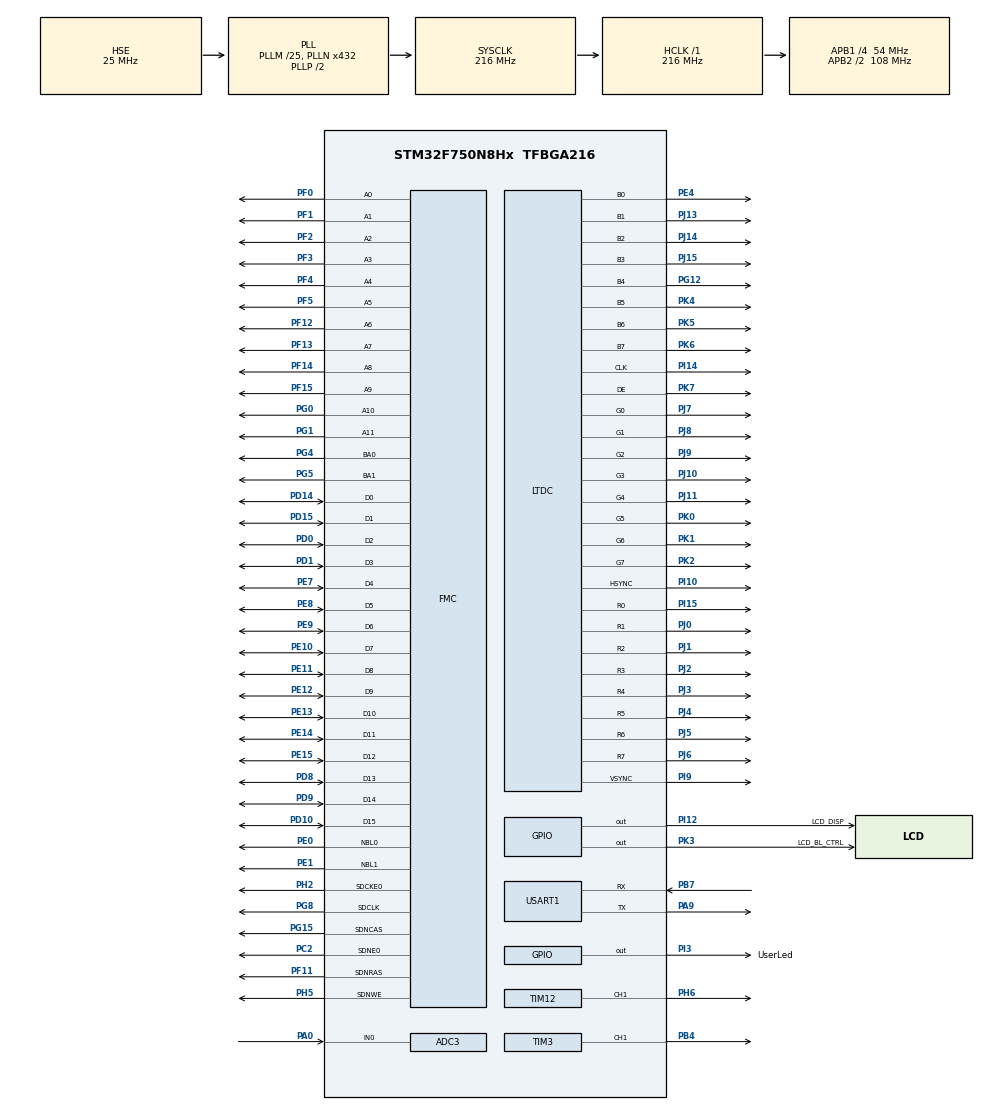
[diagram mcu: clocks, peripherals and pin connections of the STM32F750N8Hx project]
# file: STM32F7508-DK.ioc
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SH.FMC_D7_DA7.0=FMC_D7,sd-16b-d1
PK5.Signal=LTDC_B6
VP_SYS_VS_tim6.Mode=TIM6
PJ9.Mode=RGB888
SH.FMC_A0.0=FMC_A0,12b-sda1
CORTEX_M7.BaseAddress-Cortex_Memory_Protection_Unit_Region3_Settings=0x90000000
NVIC.TIM6_DAC_IRQn=true\:0\:0\:false\:false\:true\:false\:false\:true
PK0.Mode=RGB888
PG8.Signal=FMC_SDCLK
PG4.Signal=FMC_A14_BA0
PJ10.GPIO_Speed=GPIO_SPEED_FREQ_HIGH
PG0.Signal=FMC_A10
CORTEX_M7.PREFETCH_ENABLE=1
CORTEX_M7.AccessPermission-Cortex_Memory_Protection_Unit_Region2_Settings=MPU_REGION_FULL_ACCESS
PJ8.GPIO_Speed=GPIO_SPEED_FREQ_HIGH
PK1.Signal=LTDC_G6
SH.FMC_D5_DA5.0=FMC_D5,sd-16b-d1
VP_STMicroelectronics.X-CUBE-TOUCHGFX_VS_GraphicsJjApplication_4.16.0.Mode=GraphicsJjApplication
CORTEX_M7.Enable-Cortex_Memory_Protection_Unit_Region5_Settings=MPU_REGION_ENABLE
RCC.SYSCLKSource=RCC_SYSCLKSOURCE_PLLCLK
PJ10.Signal=LTDC_G3
SH.FMC_A15_BA1.0=FMC_BA1,FourSdramBanks1
SH.FMC_D9_DA9.0=FMC_D9,sd-16b-d1
STMicroelectronics.X-CUBE-TOUCHGFX.4.16.0.tgfx_hardware_accelerator=dma_2d
CORTEX_M7.Enable-Cortex_Memory_Protection_Unit_Region0_Settings=MPU_REGION_ENABLE
FREERTOS.INCLUDE_pcTaskGetTaskName=0
CORTEX_M7.IsBufferable-Cortex_Memory_Protection_Unit_Region1_Settings=MPU_ACCESS_NOT_BUFFERABLE
PH5.Signal=FMC_SDNWE
NVIC.DMA2D_IRQn=true\:5\:0\:true\:false\:true\:false\:true\:true
SH.FMC_SDNWE.0=FMC_SDNWE,12b-sda1
SH.FMC_D11_DA11.0=FMC_D11,sd-16b-d1
PJ5.Mode=RGB888
RCC.APB2TimFreq_Value=216000000
PH1/OSC_OUT.Signal=RCC_OSC_OUT
PD0.Signal=FMC_D2_DA2
PD8.Signal=FMC_D13_DA13
PE1.Signal=FMC_NBL1
CORTEX_M7.Size-Cortex_Memory_Protection_Unit_Region5_Settings=MPU_REGION_SIZE_1MB
PJ14.Mode=RGB888
LTDC.PixelFormat_L0=LTDC_PIXEL_FORMAT_RGB565
PK7.Mode=RGB888
SH.S_TIM12_CH1.0=TIM12_CH1,PWM Generation1 CH1
FREERTOS.INCLUDE_xQueueGetMutexHolder=1
PJ2.Mode=RGB888
PE9.Signal=FMC_D6_DA6
SH.FMC_A2.0=FMC_A2,12b-sda1
PI3.Signal=GPIO_Output
PJ1.GPIO_Speed=GPIO_SPEED_FREQ_HIGH
SH.FMC_D1_DA1.0=FMC_D1,sd-16b-d1
PF3.Signal=FMC_A3
CORTEX_M7.Size-Cortex_Memory_Protection_Unit_Region4_Settings=MPU_REGION_SIZE_16MB
PE10.Signal=FMC_D7_DA7
LTDC.HSync=41
CORTEX_M7.DisableExec-Cortex_Memory_Protection_Unit_Region1_Settings=MPU_INSTRUCTION_ACCESS_DISABLE
PJ14.Signal=LTDC_B2
Mcu.Package=TFBGA216
PI10.GPIO_Speed=GPIO_SPEED_FREQ_HIGH
NVIC.TimeBase=TIM6_DAC_IRQn
PK6.GPIO_Speed=GPIO_SPEED_FREQ_HIGH
PJ4.Signal=LTDC_R5
ADC3.Rank-0\#ChannelRegularConversion=1
NVIC.TimeBaseIP=TIM6
CORTEX_M7.BaseAddress-Cortex_Memory_Protection_Unit_Region4_Settings=0x90000000
SH.FMC_A1.0=FMC_A1,12b-sda1
PH2.Signal=FMC_SDCKE0
RCC.APB2CLKDivider=RCC_HCLK_DIV2
PJ3.GPIO_Speed=GPIO_SPEED_FREQ_HIGH
SH.FMC_SDCLK.0=FMC_SDCLK,12b-sda1
LTDC.VSync=10
PF14.Signal=FMC_A8
RCC.APB1TimFreq_Value=108000000
CORTEX_M7.Enable-Cortex_Memory_Protection_Unit_Region1_Settings=MPU_REGION_ENABLE
VP_DMA2D_VS_DMA2D.Mode=DMA2D_Activate
PJ13.Mode=RGB888
PJ1.Mode=RGB888
SH.FMC_D3_DA3.0=FMC_D3,sd-16b-d1
PD15.Signal=FMC_D1_DA1
CORTEX_M7.IsBufferable-Cortex_Memory_Protection_Unit_Region0_Settings=MPU_ACCESS_BUFFERABLE
PJ5.GPIO_Speed=GPIO_SPEED_FREQ_HIGH
PG12.Signal=LTDC_B4
PI14.GPIO_Speed=GPIO_SPEED_FREQ_HIGH
FREERTOS.INCLUDE_xTimerPendFunctionCall=1
CORTEX_M7.AccessPermission-Cortex_Memory_Protection_Unit_Region3_Settings=MPU_REGION_NO_ACCESS
PK4.Signal=LTDC_B5
SH.FMC_A4.0=FMC_A4,12b-sda1
FREERTOS.Tasks01=TouchGFXTask,24,8192,TouchGFX_Task,As weak,NULL,Dynamic,NULL,NULL;BlinkTask,8,128,StartBlinkTask,Default,NULL,Dynamic,NULL,NULL;PwmTask,24,128,StartPwmTask,Default,NULL,Dynamic,NULL,NULL
CORTEX_M7.IsCacheable-Cortex_Memory_Protection_Unit_Region5_Settings=MPU_ACCESS_CACHEABLE
PG5.Signal=FMC_A15_BA1
SH.FMC_D10_DA10.0=FMC_D10,sd-16b-d1
CORTEX_M7.IsBufferable-Cortex_Memory_Protection_Unit_Region2_Settings=MPU_ACCESS_BUFFERABLE
FREERTOS.INCLUDE_vTaskDelayUntil=1
CORTEX_M7.IsCacheable-Cortex_Memory_Protection_Unit_Region0_Settings=MPU_ACCESS_CACHEABLE
CORTEX_M7.Enable-Cortex_Memory_Protection_Unit_Region4_Settings=MPU_REGION_ENABLE
PI10.Mode=RGB888
PC2.Signal=FMC_SDNE0
PD1.Signal=FMC_D3_DA3
PI12.Signal=GPIO_Output
STMicroelectronics.X-CUBE-TOUCHGFX.4.16.0.tgfx_buffering_strategy=Double
RCC.APB1CLKDivider=RCC_HCLK_DIV4
PJ11.Signal=LTDC_G4
LTDC.ImageWidth_L0=480
PD10.Signal=FMC_D15_DA15
PJ6.Mode=RGB888
SH.FMC_A3.0=FMC_A3,12b-sda1
PJ7.Signal=LTDC_G0
PJ3.Signal=LTDC_R4
SH.FMC_D15_DA15.0=FMC_D15,sd-16b-d1
CORTEX_M7.ART_ACCLERATOR_ENABLE=1
PA9.Signal=USART1_TX
CORTEX_M7.IsCacheable-Cortex_Memory_Protection_Unit_Region3_Settings=MPU_ACCESS_NOT_CACHEABLE
CORTEX_M7.BaseAddress-Cortex_Memory_Protection_Unit_Region0_Settings=0x20000000
CORTEX_M7.AccessPermission-Cortex_Memory_Protection_Unit_Region5_Settings=MPU_REGION_FULL_ACCESS
PJ13.GPIO_Speed=GPIO_SPEED_FREQ_HIGH
CORTEX_M7.Enable-Cortex_Memory_Protection_Unit_Region2_Settings=MPU_REGION_ENABLE
FREERTOS.MEMORY_ALLOCATION=2
PJ15.Signal=LTDC_B3
PJ14.GPIO_Speed=GPIO_SPEED_FREQ_HIGH
SH.FMC_A6.0=FMC_A6,12b-sda1
PE14.Signal=FMC_D11_DA11
PE15.Signal=FMC_D12_DA12
PE8.Signal=FMC_D5_DA5
CORTEX_M7.AccessPermission-Cortex_Memory_Protection_Unit_Region0_Settings=MPU_REGION_FULL_ACCESS
PF13.Signal=FMC_A7
SH.FMC_SDNCAS.0=FMC_SDNCAS,12b-sda1
PJ15.Mode=RGB888
PK1.GPIO_Speed=GPIO_SPEED_FREQ_HIGH
FREERTOS.configUSE_COUNTING_SEMAPHORES=1
PK4.Mode=RGB888
SH.FMC_A5.0=FMC_A5,12b-sda1
LTDC.Alpha_L0=255
PJ6.GPIO_Speed=GPIO_SPEED_FREQ_HIGH
PJ8.Signal=LTDC_G1
ProjectManager.HeapSize=0x1000
PK3.GPIO_Label=LCD_BL_CTRL
PH6.Signal=S_TIM12_CH1
FREERTOS.configUSE_RECURSIVE_MUTEXES=1
PG12.GPIO_Speed=GPIO_SPEED_FREQ_HIGH
STMicroelectronics.X-CUBE-TOUCHGFX.4.16.0.tgfx_vsync=vsync_ltdc
PJ10.Mode=RGB888
CORTEX_M7.DisableExec-Cortex_Memory_Protection_Unit_Region2_Settings=MPU_INSTRUCTION_ACCESS_DISABLE
NVIC.PriorityGroup=NVIC_PRIORITYGROUP_4
CORTEX_M7.IsBufferable-Cortex_Memory_Protection_Unit_Region5_Settings=MPU_ACCESS_BUFFERABLE
PJ4.Mode=RGB888
PC15/OSC32_OUT.Signal=RCC_OSC32_OUT
PF4.Signal=FMC_A4
PK5.GPIO_Speed=GPIO_SPEED_FREQ_HIGH
Mcu.Family=STM32F7
PK7.Signal=LTDC_DE
PK3.Signal=GPIO_Output
SH.FMC_A8.0=FMC_A8,12b-sda1
CORTEX_M7.DisableExec-Cortex_Memory_Protection_Unit_Region4_Settings=MPU_INSTRUCTION_ACCESS_DISABLE
RCC.CortexFreq_Value=216000000
PK2.GPIO_Speed=GPIO_SPEED_FREQ_HIGH
SH.FMC_D14_DA14.0=FMC_D14,sd-16b-d1
LTDC.HBP=13
SH.FMC_NBL0.0=FMC_NBL0,Sd2ByteEnable1
SH.FMC_D6_DA6.0=FMC_D6,sd-16b-d1
PA0/WKUP.Signal=ADCx_IN0
PC14/OSC32_IN.Mode=LSE-External-Oscillator
SH.FMC_A14_BA0.0=FMC_BA0,FourSdramBanks1
SH.FMC_A11.0=FMC_A11,12b-sda1
PI9.GPIO_Speed=GPIO_SPEED_FREQ_HIGH
PJ2.GPIO_Speed=GPIO_SPEED_FREQ_HIGH
ADC3.Channel-0\#ChannelRegularConversion=ADC_CHANNEL_0
PJ9.GPIO_Speed=GPIO_SPEED_FREQ_HIGH
PG15.Signal=FMC_SDNCAS
CORTEX_M7.IsBufferable-Cortex_Memory_Protection_Unit_Region3_Settings=MPU_ACCESS_NOT_BUFFERABLE
ProjectManager.StackSize=0x1000
VP_FREERTOS_VS_CMSIS_V2.Mode=CMSIS_V2
PJ6.Signal=LTDC_R7
PJ11.GPIO_Speed=GPIO_SPEED_FREQ_HIGH
SH.FMC_A7.0=FMC_A7,12b-sda1
PJ2.Signal=LTDC_R3
STMicroelectronics.X-CUBE-TOUCHGFX.4.16.0.tgfx_location=By Address
PH0/OSC_IN.Mode=HSE-External-Oscillator
RCC.HCLKFreq_Value=216000000
SH.FMC_NBL1.0=FMC_NBL1,Sd2ByteEnable1
LTDC.WindowX1_L0=480
PF12.Signal=FMC_A6
PI9.Mode=RGB888
PK2.Mode=RGB888
SH.FMC_A10.0=FMC_A10,12b-sda1
RCC.AHBFreq_Value=216000000
TIM3.Channel-PWM\ Generation1\ CH1=TIM_CHANNEL_1
CORTEX_M7.BaseAddress-Cortex_Memory_Protection_Unit_Region5_Settings=0x90000000
RCC.HSE_VALUE=25000000
FREERTOS.configUSE_TIMERS=1
STMicroelectronics.X-CUBE-TOUCHGFX.4.16.0.tgfx_display_interface=disp_ltdc
SH.FMC_D8_DA8.0=FMC_D8,sd-16b-d1
CORTEX_M7.Size-Cortex_Memory_Protection_Unit_Region2_Settings=MPU_REGION_SIZE_8MB
PI14.Mode=RGB888
SH.FMC_D2_DA2.0=FMC_D2,sd-16b-d1
CORTEX_M7.IsCacheable-Cortex_Memory_Protection_Unit_Region2_Settings=MPU_ACCESS_CACHEABLE
PE13.Signal=FMC_D10_DA10
PE4.GPIO_Speed=GPIO_SPEED_FREQ_HIGH
PK6.Mode=RGB888
PF11.Signal=FMC_SDNRAS
PJ7.GPIO_Speed=GPIO_SPEED_FREQ_HIGH
LTDC.HFP=32
PB7.Signal=USART1_RX
SH.ADCx_IN0.0=ADC3_IN0,IN0
FREERTOS.INCLUDE_vTaskCleanUpResources=0
SH.S_TIM3_CH1.0=TIM3_CH1,PWM Generation1 CH1
PE4.Mode=RGB888
SH.FMC_SDNRAS.0=FMC_SDNRAS,12b-sda1
DMA2D.ColorMode=DMA2D_OUTPUT_ARGB8888
LTDC.ActiveW=480
PH1/OSC_OUT.Mode=HSE-External-Oscillator
PE4.Signal=LTDC_B0
CORTEX_M7.DisableExec-Cortex_Memory_Protection_Unit_Region0_Settings=MPU_INSTRUCTION_ACCESS_DISABLE
FREERTOS.configTOTAL_HEAP_SIZE=65536
STMicroelectronics.X-CUBE-TOUCHGFX.4.16.0.tgfx_address1=0xC0000000
STMicroelectronics.X-CUBE-TOUCHGFX.4.16.0.tgfx_address2=0xC003FC00
PJ0.Mode=RGB888
PJ9.Signal=LTDC_G2
SH.FMC_D0_DA0.0=FMC_D0,sd-16b-d1
CORTEX_M7.BaseAddress-Cortex_Memory_Protection_Unit_Region1_Settings=0xC0000000
PC14/OSC32_IN.Signal=RCC_OSC32_IN
SH.FMC_A9.0=FMC_A9,12b-sda1
PJ1.Signal=LTDC_R2
SH.FMC_D4_DA4.0=FMC_D4,sd-16b-d1
PI12.GPIO_Label=LCD_DISP
ADC3.ClockPrescaler=ADC_CLOCK_SYNC_PCLK_DIV8
RCC.PLLSAIN=100
PF5.Signal=FMC_A5
CORTEX_M7.Size-Cortex_Memory_Protection_Unit_Region1_Settings=MPU_REGION_SIZE_512MB
RCC.PLLSAIR=5
PJ7.Mode=RGB888
PF0.Signal=FMC_A0
PK4.GPIO_Speed=GPIO_SPEED_FREQ_HIGH
PH2.Mode=SdramChipSelect1_1
PE7.Signal=FMC_D4_DA4
PI15.Mode=RGB888
PB4.Signal=S_TIM3_CH1
PK1.Mode=RGB888
RCC.PLLSourceVirtual=RCC_PLLSOURCE_HSE
PK6.Signal=LTDC_B7
NVIC.LTDC_IRQn=true\:5\:0\:true\:false\:true\:false\:true\:true
PK2.Signal=LTDC_G7
CORTEX_M7.CPU_ICache=Enabled
LTDC.WindowY1_L0=272
PJ8.Mode=RGB888
PG1.Signal=FMC_A11
PI14.Signal=LTDC_CLK
PC2.Mode=SdramChipSelect1_1
PI10.Signal=LTDC_HSYNC
PD9.Signal=FMC_D14_DA14
FREERTOS.configUSE_APPLICATION_TASK_TAG=1
CORTEX_M7.BaseAddress-Cortex_Memory_Protection_Unit_Region2_Settings=0xC0000000
PJ11.Mode=RGB888
FREERTOS.INCLUDE_uxTaskGetStackHighWaterMark=1
USART1.VirtualMode-Asynchronous=VM_ASYNC
FREERTOS.configUSE_IDLE_HOOK=1
CORTEX_M7.MPU_Control=MPU_PRIVILEGED_DEFAULT
PA9.Mode=Asynchronous
PK0.GPIO_Speed=GPIO_SPEED_FREQ_HIGH
ADC3.SamplingTime-0\#ChannelRegularConversion=ADC_SAMPLETIME_3CYCLES
PJ0.GPIO_Speed=GPIO_SPEED_FREQ_HIGH
CORTEX_M7.IsBufferable-Cortex_Memory_Protection_Unit_Region4_Settings=MPU_ACCESS_BUFFERABLE
ProjectManager.TargetToolchain=STM32CubeIDE
FREERTOS.configUSE_TRACE_FACILITY=1
SH.FMC_D13_DA13.0=FMC_D13,sd-16b-d1
LTDC.ActiveH=272
CORTEX_M7.DisableExec-Cortex_Memory_Protection_Unit_Region3_Settings=MPU_INSTRUCTION_ACCESS_DISABLE
PF2.Signal=FMC_A2
STMicroelectronics.X-CUBE-TOUCHGFX.4.16.0.ApplicationCcGraphicsJjApplication=TouchGFXOoGenerator
RCC.USBFreq_Value=216000000
PE11.Signal=FMC_D8_DA8
PK0.Signal=LTDC_G5
PK5.Mode=RGB888
board=custom
PG12.Mode=RGB888
PJ15.GPIO_Speed=GPIO_SPEED_FREQ_HIGH
RCC.VCOOutputFreq_Value=432000000
PI9.Signal=LTDC_VSYNC
PJ3.Mode=RGB888
FREERTOS.INCLUDE_eTaskGetState=1
PH0/OSC_IN.Signal=RCC_OSC_IN
TIM12.Channel-PWM\ Generation1\ CH1=TIM_CHANNEL_1
RCC.APB2Freq_Value=108000000
LTDC.Layers=0
PK7.GPIO_Speed=GPIO_SPEED_FREQ_HIGH
SH.FMC_D12_DA12.0=FMC_D12,sd-16b-d1
PF15.Signal=FMC_A9
PF1.Signal=FMC_A1
PJ0.Signal=LTDC_R1
PE0.Signal=FMC_NBL0
Mcu.Name=STM32F750N8Hx
CORTEX_M7.Size-Cortex_Memory_Protection_Unit_Region0_Settings=MPU_REGION_SIZE_512KB
PE12.Signal=FMC_D9_DA9
FREERTOS.INCLUDE_xSemaphoreGetMutexHolder=1
CORTEX_M7.AccessPermission-Cortex_Memory_Protection_Unit_Region1_Settings=MPU_REGION_NO_ACCESS
CORTEX_M7.IsCacheable-Cortex_Memory_Protection_Unit_Region1_Settings=MPU_ACCESS_NOT_CACHEABLE
PD14.Signal=FMC_D0_DA0
RCC.SYSCLKFreq_VALUE=216000000
PI15.GPIO_Speed=GPIO_SPEED_FREQ_HIGH
PJ5.Signal=LTDC_R6
PC15/OSC32_OUT.Mode=LSE-External-Oscillator
PB7.Mode=Asynchronous
CORTEX_M7.Enable-Cortex_Memory_Protection_Unit_Region3_Settings=MPU_REGION_ENABLE
CORTEX_M7.Size-Cortex_Memory_Protection_Unit_Region3_Settings=MPU_REGION_SIZE_512MB
RCC.HSI_VALUE=16000000
PI3.GPIO_Label=UserLed
RCC.PLLM=25
RCC.PLLN=432
PI15.Signal=LTDC_R0
CORTEX_M7.CPU_DCache=Enabled
PJ4.GPIO_Speed=GPIO_SPEED_FREQ_HIGH
RCC.APB1Freq_Value=54000000
ADC3.NbrOfConversionFlag=1
VP_CRC_VS_CRC.Mode=CRC_Activate
LTDC.ImageHeight_L0=272
CORTEX_M7.AccessPermission-Cortex_Memory_Protection_Unit_Region4_Settings=MPU_REGION_FULL_ACCESS
PJ13.Signal=LTDC_B1
CORTEX_M7.IsCacheable-Cortex_Memory_Protection_Unit_Region4_Settings=MPU_ACCESS_CACHEABLE

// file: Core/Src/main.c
/* USER CODE BEGIN Header */
/**
  ******************************************************************************
  * @file           : main.c
  * @brief          : Main program body
  ******************************************************************************
  * @attention
  *
  * <h2><center>&copy; Copyright (c) 2020 STMicroelectronics.
  * All rights reserved.</center></h2>
  *
  * This software component is licensed by ST under Ultimate Liberty license
  * SLA0044, the "License"; You may not use this file except in compliance with
  * the License. You may obtain a copy of the License at:
  *                             www.st.com/SLA0044
  *
  ******************************************************************************
  */
/* USER CODE END Header */
#include "main.h"
#include "cmsis_os.h"
#include "app_touchgfx.h"

/* USER CODE BEGIN Includes */
#include "stm32f7508_discovery_sdram.h"
/* USER CODE END Includes */

ADC_HandleTypeDef hadc3;

CRC_HandleTypeDef hcrc;

DMA2D_HandleTypeDef hdma2d;

LTDC_HandleTypeDef hltdc;

TIM_HandleTypeDef htim3;
TIM_HandleTypeDef htim12;

UART_HandleTypeDef huart1;

SDRAM_HandleTypeDef hsdram1;

/* Definitions for TouchGFXTask */
osThreadId_t TouchGFXTaskHandle;
const osThreadAttr_t TouchGFXTask_attributes = {
  .name = "TouchGFXTask",
  .priority = (osPriority_t) osPriorityNormal,
  .stack_size = 8192 * 4
};
/* Definitions for BlinkTask */
osThreadId_t BlinkTaskHandle;
const osThreadAttr_t BlinkTask_attributes = {
  .name = "BlinkTask",
  .priority = (osPriority_t) osPriorityLow,
  .stack_size = 128 * 4
};
/* Definitions for PwmTask */
osThreadId_t PwmTaskHandle;
const osThreadAttr_t PwmTask_attributes = {
  .name = "PwmTask",
  .priority = (osPriority_t) osPriorityNormal,
  .stack_size = 128 * 4
};

void SystemClock_Config(void);
static void MPU_Config(void);
static void MX_GPIO_Init(void);
static void MX_CRC_Init(void);
static void MX_DMA2D_Init(void);
static void MX_FMC_Init(void);
static void MX_LTDC_Init(void);
static void MX_USART1_UART_Init(void);
static void MX_TIM3_Init(void);
static void MX_ADC3_Init(void);
static void MX_TIM12_Init(void);
void TouchGFX_Task(void *argument);
void StartBlinkTask(void *argument);
void StartPwmTask(void *argument);

/* USER CODE BEGIN PFP */

void setPWM(TIM_HandleTypeDef timer, uint32_t channel, uint16_t period, uint16_t pulse);

/* USER CODE END PFP */

int main(void)
{

  /* MPU Configuration--------------------------------------------------------*/
  MPU_Config();

  /* Enable I-Cache---------------------------------------------------------*/
  SCB_EnableICache();

  /* Enable D-Cache---------------------------------------------------------*/
  SCB_EnableDCache();

  /* MCU Configuration--------------------------------------------------------*/

  /* Reset of all peripherals, Initializes the Flash interface and the Systick. */
  HAL_Init();

  /* Configure the system clock */
  SystemClock_Config();

  /* Initialize all configured peripherals */
  MX_GPIO_Init();
  MX_CRC_Init();
  MX_DMA2D_Init();
  MX_FMC_Init();
  MX_LTDC_Init();
  MX_USART1_UART_Init();
  MX_TIM3_Init();
  MX_ADC3_Init();
  MX_TIM12_Init();
  MX_TouchGFX_Init();

  /* Init scheduler */
  osKernelInitialize();

  /* Create the thread(s) */
  /* creation of TouchGFXTask */
  TouchGFXTaskHandle = osThreadNew(TouchGFX_Task, NULL, &TouchGFXTask_attributes);

  /* creation of BlinkTask */
  BlinkTaskHandle = osThreadNew(StartBlinkTask, NULL, &BlinkTask_attributes);

  /* creation of PwmTask */
  PwmTaskHandle = osThreadNew(StartPwmTask, NULL, &PwmTask_attributes);

  /* Start scheduler */
  osKernelStart();

  /* We should never get here as control is now taken by the scheduler */
  /* Infinite loop */
  while (1)
  {

  }
}

void SystemClock_Config(void)
{
  RCC_OscInitTypeDef RCC_OscInitStruct = {0};
  RCC_ClkInitTypeDef RCC_ClkInitStruct = {0};
  RCC_PeriphCLKInitTypeDef PeriphClkInitStruct = {0};

  /** Configure LSE Drive Capability
  */
  HAL_PWR_EnableBkUpAccess();
  /** Configure the main internal regulator output voltage
  */
  __HAL_RCC_PWR_CLK_ENABLE();
  __HAL_PWR_VOLTAGESCALING_CONFIG(PWR_REGULATOR_VOLTAGE_SCALE1);
  /** Initializes the RCC Oscillators according to the specified parameters
  * in the RCC_OscInitTypeDef structure.
  */
  RCC_OscInitStruct.OscillatorType = RCC_OSCILLATORTYPE_HSE;
  RCC_OscInitStruct.HSEState = RCC_HSE_ON;
  RCC_OscInitStruct.PLL.PLLState = RCC_PLL_ON;
  RCC_OscInitStruct.PLL.PLLSource = RCC_PLLSOURCE_HSE;
  RCC_OscInitStruct.PLL.PLLM = 25;
  RCC_OscInitStruct.PLL.PLLN = 432;
  RCC_OscInitStruct.PLL.PLLP = RCC_PLLP_DIV2;
  RCC_OscInitStruct.PLL.PLLQ = 2;
  if (HAL_RCC_OscConfig(&RCC_OscInitStruct) != HAL_OK)
  {
    Error_Handler();
  }
  /** Activate the Over-Drive mode
  */
  if (HAL_PWREx_EnableOverDrive() != HAL_OK)
  {
    Error_Handler();
  }
  /** Initializes the CPU, AHB and APB buses clocks
  */
  RCC_ClkInitStruct.ClockType = RCC_CLOCKTYPE_HCLK|RCC_CLOCKTYPE_SYSCLK
                              |RCC_CLOCKTYPE_PCLK1|RCC_CLOCKTYPE_PCLK2;
  RCC_ClkInitStruct.SYSCLKSource = RCC_SYSCLKSOURCE_PLLCLK;
  RCC_ClkInitStruct.AHBCLKDivider = RCC_SYSCLK_DIV1;
  RCC_ClkInitStruct.APB1CLKDivider = RCC_HCLK_DIV4;
  RCC_ClkInitStruct.APB2CLKDivider = RCC_HCLK_DIV2;

  if (HAL_RCC_ClockConfig(&RCC_ClkInitStruct, FLASH_LATENCY_7) != HAL_OK)
  {
    Error_Handler();
  }
  PeriphClkInitStruct.PeriphClockSelection = RCC_PERIPHCLK_LTDC|RCC_PERIPHCLK_USART1;
  PeriphClkInitStruct.PLLSAI.PLLSAIN = 100;
  PeriphClkInitStruct.PLLSAI.PLLSAIR = 5;
  PeriphClkInitStruct.PLLSAI.PLLSAIQ = 2;
  PeriphClkInitStruct.PLLSAI.PLLSAIP = RCC_PLLSAIP_DIV2;
  PeriphClkInitStruct.PLLSAIDivQ = 1;
  PeriphClkInitStruct.PLLSAIDivR = RCC_PLLSAIDIVR_2;
  PeriphClkInitStruct.Usart1ClockSelection = RCC_USART1CLKSOURCE_PCLK2;
  if (HAL_RCCEx_PeriphCLKConfig(&PeriphClkInitStruct) != HAL_OK)
  {
    Error_Handler();
  }
}

static void MX_ADC3_Init(void)
{

  ADC_ChannelConfTypeDef sConfig = {0};

  /** Configure the global features of the ADC (Clock, Resolution, Data Alignment and number of conversion)
  */
  hadc3.Instance = ADC3;
  hadc3.Init.ClockPrescaler = ADC_CLOCK_SYNC_PCLK_DIV8;
  hadc3.Init.Resolution = ADC_RESOLUTION_12B;
  hadc3.Init.ScanConvMode = ADC_SCAN_DISABLE;
  hadc3.Init.ContinuousConvMode = DISABLE;
  hadc3.Init.DiscontinuousConvMode = DISABLE;
  hadc3.Init.ExternalTrigConvEdge = ADC_EXTERNALTRIGCONVEDGE_NONE;
  hadc3.Init.ExternalTrigConv = ADC_SOFTWARE_START;
  hadc3.Init.DataAlign = ADC_DATAALIGN_RIGHT;
  hadc3.Init.NbrOfConversion = 1;
  hadc3.Init.DMAContinuousRequests = DISABLE;
  hadc3.Init.EOCSelection = ADC_EOC_SINGLE_CONV;
  if (HAL_ADC_Init(&hadc3) != HAL_OK)
  {
    Error_Handler();
  }
  /** Configure for the selected ADC regular channel its corresponding rank in the sequencer and its sample time.
  */
  sConfig.Channel = ADC_CHANNEL_0;
  sConfig.Rank = ADC_REGULAR_RANK_1;
  sConfig.SamplingTime = ADC_SAMPLETIME_3CYCLES;
  if (HAL_ADC_ConfigChannel(&hadc3, &sConfig) != HAL_OK)
  {
    Error_Handler();
  }

}

static void MX_CRC_Init(void)
{

  hcrc.Instance = CRC;
  hcrc.Init.DefaultPolynomialUse = DEFAULT_POLYNOMIAL_ENABLE;
  hcrc.Init.DefaultInitValueUse = DEFAULT_INIT_VALUE_ENABLE;
  hcrc.Init.InputDataInversionMode = CRC_INPUTDATA_INVERSION_NONE;
  hcrc.Init.OutputDataInversionMode = CRC_OUTPUTDATA_INVERSION_DISABLE;
  hcrc.InputDataFormat = CRC_INPUTDATA_FORMAT_BYTES;
  if (HAL_CRC_Init(&hcrc) != HAL_OK)
  {
    Error_Handler();
  }

}

static void MX_DMA2D_Init(void)
{

  hdma2d.Instance = DMA2D;
  hdma2d.Init.Mode = DMA2D_M2M;
  hdma2d.Init.ColorMode = DMA2D_OUTPUT_ARGB8888;
  hdma2d.Init.OutputOffset = 0;
  hdma2d.LayerCfg[1].InputOffset = 0;
  hdma2d.LayerCfg[1].InputColorMode = DMA2D_INPUT_ARGB8888;
  hdma2d.LayerCfg[1].AlphaMode = DMA2D_NO_MODIF_ALPHA;
  hdma2d.LayerCfg[1].InputAlpha = 0;
  if (HAL_DMA2D_Init(&hdma2d) != HAL_OK)
  {
    Error_Handler();
  }
  if (HAL_DMA2D_ConfigLayer(&hdma2d, 1) != HAL_OK)
  {
    Error_Handler();
  }

}

static void MX_LTDC_Init(void)
{

  LTDC_LayerCfgTypeDef pLayerCfg = {0};

  hltdc.Instance = LTDC;
  hltdc.Init.HSPolarity = LTDC_HSPOLARITY_AL;
  hltdc.Init.VSPolarity = LTDC_VSPOLARITY_AL;
  hltdc.Init.DEPolarity = LTDC_DEPOLARITY_AL;
  hltdc.Init.PCPolarity = LTDC_PCPOLARITY_IPC;
  hltdc.Init.HorizontalSync = 40;
  hltdc.Init.VerticalSync = 9;
  hltdc.Init.AccumulatedHBP = 53;
  hltdc.Init.AccumulatedVBP = 11;
  hltdc.Init.AccumulatedActiveW = 533;
  hltdc.Init.AccumulatedActiveH = 283;
  hltdc.Init.TotalWidth = 565;
  hltdc.Init.TotalHeigh = 285;
  hltdc.Init.Backcolor.Blue = 0;
  hltdc.Init.Backcolor.Green = 0;
  hltdc.Init.Backcolor.Red = 0;
  if (HAL_LTDC_Init(&hltdc) != HAL_OK)
  {
    Error_Handler();
  }
  pLayerCfg.WindowX0 = 0;
  pLayerCfg.WindowX1 = 480;
  pLayerCfg.WindowY0 = 0;
  pLayerCfg.WindowY1 = 272;
  pLayerCfg.PixelFormat = LTDC_PIXEL_FORMAT_RGB565;
  pLayerCfg.Alpha = 255;
  pLayerCfg.Alpha0 = 0;
  pLayerCfg.BlendingFactor1 = LTDC_BLENDING_FACTOR1_CA;
  pLayerCfg.BlendingFactor2 = LTDC_BLENDING_FACTOR2_CA;
  pLayerCfg.FBStartAdress = 0;
  pLayerCfg.ImageWidth = 480;
  pLayerCfg.ImageHeight = 272;
  pLayerCfg.Backcolor.Blue = 0;
  pLayerCfg.Backcolor.Green = 0;
  pLayerCfg.Backcolor.Red = 0;
  if (HAL_LTDC_ConfigLayer(&hltdc, &pLayerCfg, 0) != HAL_OK)
  {
    Error_Handler();
  }

}

static void MX_TIM3_Init(void)
{

  TIM_MasterConfigTypeDef sMasterConfig = {0};
  TIM_OC_InitTypeDef sConfigOC = {0};

  htim3.Instance = TIM3;
  htim3.Init.Prescaler = 0;
  htim3.Init.CounterMode = TIM_COUNTERMODE_UP;
  htim3.Init.Period = 0;
  htim3.Init.ClockDivision = TIM_CLOCKDIVISION_DIV1;
  htim3.Init.AutoReloadPreload = TIM_AUTORELOAD_PRELOAD_DISABLE;
  if (HAL_TIM_PWM_Init(&htim3) != HAL_OK)
  {
    Error_Handler();
  }
  sMasterConfig.MasterOutputTrigger = TIM_TRGO_RESET;
  sMasterConfig.MasterSlaveMode = TIM_MASTERSLAVEMODE_DISABLE;
  if (HAL_TIMEx_MasterConfigSynchronization(&htim3, &sMasterConfig) != HAL_OK)
  {
    Error_Handler();
  }
  sConfigOC.OCMode = TIM_OCMODE_PWM1;
  sConfigOC.Pulse = 0;
  sConfigOC.OCPolarity = TIM_OCPOLARITY_HIGH;
  sConfigOC.OCFastMode = TIM_OCFAST_DISABLE;
  if (HAL_TIM_PWM_ConfigChannel(&htim3, &sConfigOC, TIM_CHANNEL_1) != HAL_OK)
  {
    Error_Handler();
  }
  HAL_TIM_MspPostInit(&htim3);

}

static void MX_TIM12_Init(void)
{

  TIM_OC_InitTypeDef sConfigOC = {0};

  htim12.Instance = TIM12;
  htim12.Init.Prescaler = 0;
  htim12.Init.CounterMode = TIM_COUNTERMODE_UP;
  htim12.Init.Period = 0;
  htim12.Init.ClockDivision = TIM_CLOCKDIVISION_DIV1;
  htim12.Init.AutoReloadPreload = TIM_AUTORELOAD_PRELOAD_DISABLE;
  if (HAL_TIM_PWM_Init(&htim12) != HAL_OK)
  {
    Error_Handler();
  }
  sConfigOC.OCMode = TIM_OCMODE_PWM1;
  sConfigOC.Pulse = 0;
  sConfigOC.OCPolarity = TIM_OCPOLARITY_HIGH;
  sConfigOC.OCFastMode = TIM_OCFAST_DISABLE;
  if (HAL_TIM_PWM_ConfigChannel(&htim12, &sConfigOC, TIM_CHANNEL_1) != HAL_OK)
  {
    Error_Handler();
  }
  HAL_TIM_MspPostInit(&htim12);

}

static void MX_USART1_UART_Init(void)
{

  huart1.Instance = USART1;
  huart1.Init.BaudRate = 115200;
  huart1.Init.WordLength = UART_WORDLENGTH_8B;
  huart1.Init.StopBits = UART_STOPBITS_1;
  huart1.Init.Parity = UART_PARITY_NONE;
  huart1.Init.Mode = UART_MODE_TX_RX;
  huart1.Init.HwFlowCtl = UART_HWCONTROL_NONE;
  huart1.Init.OverSampling = UART_OVERSAMPLING_16;
  huart1.Init.OneBitSampling = UART_ONE_BIT_SAMPLE_DISABLE;
  huart1.AdvancedInit.AdvFeatureInit = UART_ADVFEATURE_NO_INIT;
  if (HAL_UART_Init(&huart1) != HAL_OK)
  {
    Error_Handler();
  }

}

/* FMC initialization function */
static void MX_FMC_Init(void)
{

  FMC_SDRAM_TimingTypeDef SdramTiming = {0};

  /** Perform the SDRAM1 memory initialization sequence
  */
  hsdram1.Instance = FMC_SDRAM_DEVICE;
  /* hsdram1.Init */
  hsdram1.Init.SDBank = FMC_SDRAM_BANK1;
  hsdram1.Init.ColumnBitsNumber = FMC_SDRAM_COLUMN_BITS_NUM_8;
  hsdram1.Init.RowBitsNumber = FMC_SDRAM_ROW_BITS_NUM_12;
  hsdram1.Init.MemoryDataWidth = FMC_SDRAM_MEM_BUS_WIDTH_16;
  hsdram1.Init.InternalBankNumber = FMC_SDRAM_INTERN_BANKS_NUM_4;
  hsdram1.Init.CASLatency = FMC_SDRAM_CAS_LATENCY_1;
  hsdram1.Init.WriteProtection = FMC_SDRAM_WRITE_PROTECTION_DISABLE;
  hsdram1.Init.SDClockPeriod = FMC_SDRAM_CLOCK_DISABLE;
  hsdram1.Init.ReadBurst = FMC_SDRAM_RBURST_DISABLE;
  hsdram1.Init.ReadPipeDelay = FMC_SDRAM_RPIPE_DELAY_0;
  /* SdramTiming */
  SdramTiming.LoadToActiveDelay = 16;
  SdramTiming.ExitSelfRefreshDelay = 16;
  SdramTiming.SelfRefreshTime = 16;
  SdramTiming.RowCycleDelay = 16;
  SdramTiming.WriteRecoveryTime = 16;
  SdramTiming.RPDelay = 16;
  SdramTiming.RCDDelay = 16;

  if (HAL_SDRAM_Init(&hsdram1, &SdramTiming) != HAL_OK)
  {
    Error_Handler( );
  }

  /* USER CODE BEGIN FMC_Init 2 */
  BSP_SDRAM_DeInit();
  if(BSP_SDRAM_Init() != SDRAM_OK)
  {
    Error_Handler();
  }
  /* USER CODE END FMC_Init 2 */
}

static void MX_GPIO_Init(void)
{
  GPIO_InitTypeDef GPIO_InitStruct = {0};

  /* GPIO Ports Clock Enable */
  __HAL_RCC_GPIOE_CLK_ENABLE();
  __HAL_RCC_GPIOB_CLK_ENABLE();
  __HAL_RCC_GPIOG_CLK_ENABLE();
  __HAL_RCC_GPIOJ_CLK_ENABLE();
  __HAL_RCC_GPIOD_CLK_ENABLE();
  __HAL_RCC_GPIOK_CLK_ENABLE();
  __HAL_RCC_GPIOI_CLK_ENABLE();
  __HAL_RCC_GPIOF_CLK_ENABLE();
  __HAL_RCC_GPIOC_CLK_ENABLE();
  __HAL_RCC_GPIOA_CLK_ENABLE();
  __HAL_RCC_GPIOH_CLK_ENABLE();

  /*Configure GPIO pin Output Level */
  HAL_GPIO_WritePin(GPIOI, UserLed_Pin|LCD_DISP_Pin, GPIO_PIN_RESET);

  /*Configure GPIO pin Output Level */
  HAL_GPIO_WritePin(LCD_BL_CTRL_GPIO_Port, LCD_BL_CTRL_Pin, GPIO_PIN_RESET);

  /*Configure GPIO pins : UserLed_Pin LCD_DISP_Pin */
  GPIO_InitStruct.Pin = UserLed_Pin|LCD_DISP_Pin;
  GPIO_InitStruct.Mode = GPIO_MODE_OUTPUT_PP;
  GPIO_InitStruct.Pull = GPIO_NOPULL;
  GPIO_InitStruct.Speed = GPIO_SPEED_FREQ_LOW;
  HAL_GPIO_Init(GPIOI, &GPIO_InitStruct);

  /*Configure GPIO pin : LCD_BL_CTRL_Pin */
  GPIO_InitStruct.Pin = LCD_BL_CTRL_Pin;
  GPIO_InitStruct.Mode = GPIO_MODE_OUTPUT_PP;
  GPIO_InitStruct.Pull = GPIO_NOPULL;
  GPIO_InitStruct.Speed = GPIO_SPEED_FREQ_LOW;
  HAL_GPIO_Init(LCD_BL_CTRL_GPIO_Port, &GPIO_InitStruct);

}

/* USER CODE BEGIN 4 */

uint32_t GetPotVal(void)
{
	if (HAL_ADC_Start(&hadc3) == HAL_OK)
	{
		if (HAL_ADC_PollForConversion(&hadc3, 1000) == HAL_OK)
		{
			return HAL_ADC_GetValue(&hadc3);
		}
	}
	return  0xFFFFFFFF;
}

void setPWM(TIM_HandleTypeDef timer, uint32_t channel, uint16_t period, uint16_t pulse)
{
	HAL_TIM_PWM_Stop(&timer, channel); // stop generation of pwm
	TIM_OC_InitTypeDef sConfigOC;
	timer.Init.Period = period; // set the period duration
	HAL_TIM_PWM_Init(&timer); // reinititialise with new period value
	sConfigOC.OCMode = TIM_OCMODE_PWM1;
	sConfigOC.Pulse = pulse; // set the pulse duration
	sConfigOC.OCPolarity = TIM_OCPOLARITY_HIGH;
	sConfigOC.OCFastMode = TIM_OCFAST_DISABLE;
	HAL_TIM_PWM_ConfigChannel(&timer, &sConfigOC, channel);
	HAL_TIM_PWM_Start(&timer, channel); // start pwm generation
}

void setPWMtim12(int value)
{
	setPWM(htim12, TIM_CHANNEL_1, 4095, value);
}

/* USER CODE END 4 */

__weak void TouchGFX_Task(void *argument)
{
  /* USER CODE BEGIN 5 */
  MX_TouchGFX_Process();
  /* Infinite loop */
  for(;;)
  {
    osDelay(1);
  }
  /* USER CODE END 5 */
}

void StartBlinkTask(void *argument)
{
  /* USER CODE BEGIN StartBlinkTask */
  /* Infinite loop */
  for(;;)
  {
//	  HAL_GPIO_TogglePin(GPIOI, UserLed_Pin);
//	  osDelay(100);
	  osDelay(1);
  }
  /* USER CODE END StartBlinkTask */
}

void StartPwmTask(void *argument)
{
  /* USER CODE BEGIN StartPwmTask */
  /* Infinite loop */
  for(;;)
  {
	  if(GetPotVal() >= 100)
		  setPWM(htim3, TIM_CHANNEL_1, 4095, GetPotVal());
	  else
		  setPWM(htim3, TIM_CHANNEL_1, 4095, 0);
	  osDelay(1);
  }
  /* USER CODE END StartPwmTask */
}

/* MPU Configuration */

void MPU_Config(void)
{
  MPU_Region_InitTypeDef MPU_InitStruct = {0};

  /* Disables the MPU */
  HAL_MPU_Disable();
  /** Initializes and configures the Region and the memory to be protected
  */
  MPU_InitStruct.Enable = MPU_REGION_ENABLE;
  MPU_InitStruct.Number = MPU_REGION_NUMBER0;
  MPU_InitStruct.BaseAddress = 0x20000000;
  MPU_InitStruct.Size = MPU_REGION_SIZE_512KB;
  MPU_InitStruct.SubRegionDisable = 0x0;
  MPU_InitStruct.TypeExtField = MPU_TEX_LEVEL0;
  MPU_InitStruct.AccessPermission = MPU_REGION_FULL_ACCESS;
  MPU_InitStruct.DisableExec = MPU_INSTRUCTION_ACCESS_DISABLE;
  MPU_InitStruct.IsShareable = MPU_ACCESS_NOT_SHAREABLE;
  MPU_InitStruct.IsCacheable = MPU_ACCESS_CACHEABLE;
  MPU_InitStruct.IsBufferable = MPU_ACCESS_BUFFERABLE;

  HAL_MPU_ConfigRegion(&MPU_InitStruct);
  /** Initializes and configures the Region and the memory to be protected
  */
  MPU_InitStruct.Enable = MPU_REGION_ENABLE;
  MPU_InitStruct.Number = MPU_REGION_NUMBER1;
  MPU_InitStruct.BaseAddress = 0xC0000000;
  MPU_InitStruct.Size = MPU_REGION_SIZE_512MB;
  MPU_InitStruct.SubRegionDisable = 0x0;
  MPU_InitStruct.TypeExtField = MPU_TEX_LEVEL0;
  MPU_InitStruct.AccessPermission = MPU_REGION_NO_ACCESS;
  MPU_InitStruct.DisableExec = MPU_INSTRUCTION_ACCESS_DISABLE;
  MPU_InitStruct.IsShareable = MPU_ACCESS_NOT_SHAREABLE;
  MPU_InitStruct.IsCacheable = MPU_ACCESS_NOT_CACHEABLE;
  MPU_InitStruct.IsBufferable = MPU_ACCESS_NOT_BUFFERABLE;

  HAL_MPU_ConfigRegion(&MPU_InitStruct);
  /** Initializes and configures the Region and the memory to be protected
  */
  MPU_InitStruct.Enable = MPU_REGION_ENABLE;
  MPU_InitStruct.Number = MPU_REGION_NUMBER2;
  MPU_InitStruct.BaseAddress = 0xC0000000;
  MPU_InitStruct.Size = MPU_REGION_SIZE_8MB;
  MPU_InitStruct.SubRegionDisable = 0x0;
  MPU_InitStruct.TypeExtField = MPU_TEX_LEVEL0;
  MPU_InitStruct.AccessPermission = MPU_REGION_FULL_ACCESS;
  MPU_InitStruct.DisableExec = MPU_INSTRUCTION_ACCESS_DISABLE;
  MPU_InitStruct.IsShareable = MPU_ACCESS_NOT_SHAREABLE;
  MPU_InitStruct.IsCacheable = MPU_ACCESS_CACHEABLE;
  MPU_InitStruct.IsBufferable = MPU_ACCESS_BUFFERABLE;

  HAL_MPU_ConfigRegion(&MPU_InitStruct);
  /** Initializes and configures the Region and the memory to be protected
  */
  MPU_InitStruct.Enable = MPU_REGION_ENABLE;
  MPU_InitStruct.Number = MPU_REGION_NUMBER3;
  MPU_InitStruct.BaseAddress = 0x90000000;
  MPU_InitStruct.Size = MPU_REGION_SIZE_512MB;
  MPU_InitStruct.SubRegionDisable = 0x0;
  MPU_InitStruct.TypeExtField = MPU_TEX_LEVEL0;
  MPU_InitStruct.AccessPermission = MPU_REGION_NO_ACCESS;
  MPU_InitStruct.DisableExec = MPU_INSTRUCTION_ACCESS_DISABLE;
  MPU_InitStruct.IsShareable = MPU_ACCESS_NOT_SHAREABLE;
  MPU_InitStruct.IsCacheable = MPU_ACCESS_NOT_CACHEABLE;
  MPU_InitStruct.IsBufferable = MPU_ACCESS_NOT_BUFFERABLE;

  HAL_MPU_ConfigRegion(&MPU_InitStruct);
  /** Initializes and configures the Region and the memory to be protected
  */
  MPU_InitStruct.Enable = MPU_REGION_ENABLE;
  MPU_InitStruct.Number = MPU_REGION_NUMBER4;
  MPU_InitStruct.BaseAddress = 0x90000000;
  MPU_InitStruct.Size = MPU_REGION_SIZE_16MB;
  MPU_InitStruct.SubRegionDisable = 0x0;
  MPU_InitStruct.TypeExtField = MPU_TEX_LEVEL0;
  MPU_InitStruct.AccessPermission = MPU_REGION_FULL_ACCESS;
  MPU_InitStruct.DisableExec = MPU_INSTRUCTION_ACCESS_DISABLE;
  MPU_InitStruct.IsShareable = MPU_ACCESS_NOT_SHAREABLE;
  MPU_InitStruct.IsCacheable = MPU_ACCESS_CACHEABLE;
  MPU_InitStruct.IsBufferable = MPU_ACCESS_BUFFERABLE;

  HAL_MPU_ConfigRegion(&MPU_InitStruct);
  /** Initializes and configures the Region and the memory to be protected
  */
  MPU_InitStruct.Enable = MPU_REGION_ENABLE;
  MPU_InitStruct.Number = MPU_REGION_NUMBER5;
  MPU_InitStruct.BaseAddress = 0x90000000;
  MPU_InitStruct.Size = MPU_REGION_SIZE_1MB;
  MPU_InitStruct.SubRegionDisable = 0x0;
  MPU_InitStruct.TypeExtField = MPU_TEX_LEVEL0;
  MPU_InitStruct.AccessPermission = MPU_REGION_FULL_ACCESS;
  MPU_InitStruct.DisableExec = MPU_INSTRUCTION_ACCESS_ENABLE;
  MPU_InitStruct.IsShareable = MPU_ACCESS_NOT_SHAREABLE;
  MPU_InitStruct.IsCacheable = MPU_ACCESS_CACHEABLE;
  MPU_InitStruct.IsBufferable = MPU_ACCESS_BUFFERABLE;

  HAL_MPU_ConfigRegion(&MPU_InitStruct);
  /* Enables the MPU */
  HAL_MPU_Enable(MPU_PRIVILEGED_DEFAULT);

}
void HAL_TIM_PeriodElapsedCallback(TIM_HandleTypeDef *htim)
{
  if (htim->Instance == TIM6) {
    HAL_IncTick();
  }
}

void Error_Handler(void)
{
  /* USER CODE BEGIN Error_Handler_Debug */
  /* User can add his own implementation to report the HAL error return state */
  while(1);
  /* USER CODE END Error_Handler_Debug */
}

/************************ (C) COPYRIGHT STMicroelectronics *****END OF FILE****/
